# STM32F412Rx register map
File version: 1.0
Registers are 32-bit, read-write, reset 0x0 unless marked. A register's access mark holds for its fields unless they carry their own. Offsets are from the block's base; [hi:lo] are bit positions; {n}, {i} and the like mark numbered series; 'fields as' and 'values as' point back to an identical list.

## PWR — Power Control
Base 0x40007000
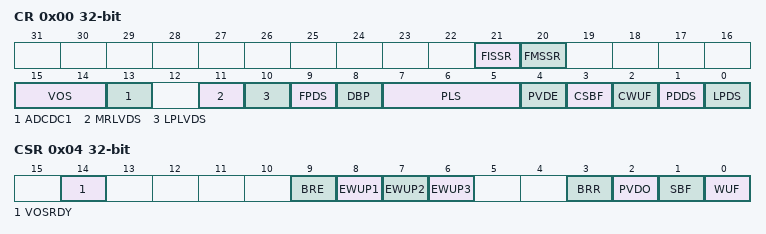
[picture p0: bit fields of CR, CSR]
0x00 CR — PWR power control register
  [21] FISSR — Flash Interface Stop while System Run
  [20] FMSSR — Flash Memory Sleep System Run
  [15:14] VOS — VOS[1:0] bits (Regulator voltage scaling output selection)
    3=SCALE1; 2=SCALE2; 1=SCALE3
  [13] ADCDC1 — Refer to AN4073 on how to use this bit
  [11] MRLVDS — Main Regulator Low Voltage in Deep Sleep mode
  [10] LPLVDS — Low Power Regulator Low Voltage in Deep Sleep mode
  [9] FPDS — Flash power down in Stop mode
  [8] DBP — Disable Backup Domain write protection
  [7:5] PLS — PLS[2:0] bits (PVD Level Selection)
    0=PVDLEVEL_0 (Voltage threshold detected by PVD 2.2 V); 1=PVDLEVEL_1 (Voltage threshold detected by PVD 2.3 V); 2=PVDLEVEL_2 (Voltage threshold detected by PVD 2.4 V); 3=PVDLEVEL_3 (Voltage threshold detected by PVD 2.5 V); 4=PVDLEVEL_4 (Voltage threshold detected by PVD 2.6 V); 5=PVDLEVEL_5 (Voltage threshold detected by PVD 2.7 V); 6=PVDLEVEL_6 (Voltage threshold detected by PVD 2.8 V); 7=PVDLEVEL_7 (Voltage threshold detected by PVD 2.9 V)
  [4] PVDE — Power Voltage Detector Enable
  [3] CSBF — Clear Standby Flag
  [2] CWUF — Clear Wakeup Flag
  [1] PDDS — Power Down Deepsleep
  [0] LPDS — Low-Power Deepsleep
    0=MAIN (Voltage Regulator in main mode during deepsleep mode); 1=LOW_POWER (Voltage Regulator in low-power mode during deepsleep mode)
0x04 CSR — PWR power control/status register
  [14] VOSRDY — Regulator voltage scaling output selection ready
  [9] BRE — Backup regulator enable
  [8] EWUP1 — Enable WKUP pin 1
  [7] EWUP2 — Enable WKUP pin 2
  [6] EWUP3 — Enable WKUP pin 3
  [3] BRR — Backup regulator ready
  [2] PVDO — PVD Output
  [1] SBF — Standby Flag
  [0] WUF — Wakeup Flag

## SYSCFG — System configuration controller
Base 0x40013800
0x00 MEMRMP — SYSCFG memory remap register
  [1:0] MEM_MODE — SYSCFG_Memory Remap Config
    0=FLASH (Main Flash memory mapped at 0x00000000); 1=SYSTEMFLASH (System Flash memory mapped at 0x00000000); 3=SRAM (SRAM1 mapped at 0x00000000); 2=FSMC (FSMC(NOR/PSRAM 1 and 2) mapped at 0x00000000)
0x04 PMC — SYSCFG peripheral mode configuration register
  [16] ADC1DC2 — Refer to AN4073 on how to use this bit
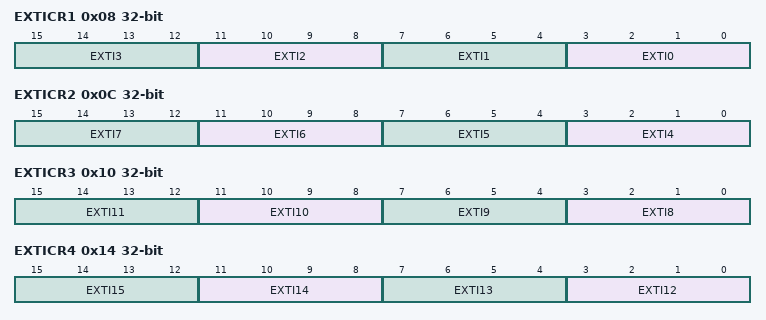
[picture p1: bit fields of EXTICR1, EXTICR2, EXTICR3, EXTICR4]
0x08 EXTICR1 — SYSCFG external interrupt configuration registers
  [4n+3:4n] EXTI{n} (n=0..3) — EXTI {n} configuration
0x0C EXTICR2 — SYSCFG external interrupt configuration registers
  [4n-13:4n-16] EXTI{n} (n=4..7) — EXTI {n} configuration
0x10 EXTICR3 — SYSCFG external interrupt configuration registers
  [4n-29:4n-32] EXTI{n} (n=8..11) — EXTI {n} configuration
0x14 EXTICR4 — SYSCFG external interrupt configuration registers
  [4n-45:4n-48] EXTI{n} (n=12..15) — EXTI {n} configuration
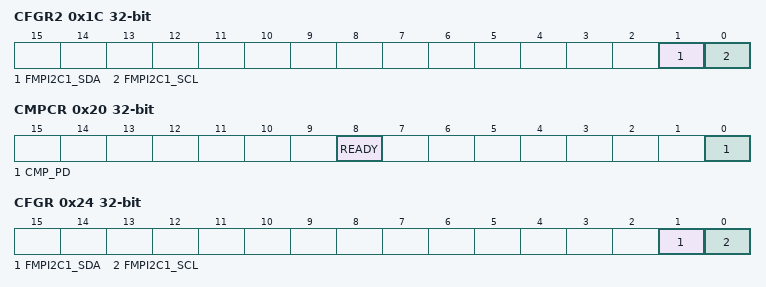
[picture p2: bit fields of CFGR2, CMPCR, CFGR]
0x1C CFGR2 — SYSCFG Configuration register2
  [1] FMPI2C1_SDA — FM+ drive capability for FMPI2C1_SDA pin
  [0] FMPI2C1_SCL — FM+ drive capability for FMPI2C1_SCL pin
0x20 CMPCR — SYSCFG Compensation cell control register
  [8] READY — Compensation cell power-down
  [0] CMP_PD — Compensation cell ready flag
0x24 CFGR — SYSCFG Configuration register
  fields as CFGR2

## EXTI — External Interrupt/Event Controller
Base 0x40013C00
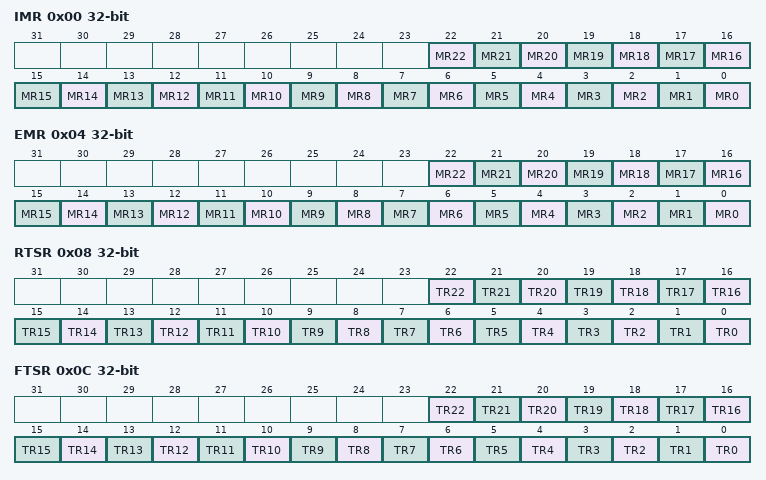
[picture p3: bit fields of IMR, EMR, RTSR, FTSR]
0x00 IMR — EXTI Interrupt mask register
  [n] MR{n} (n=0..22) — Interrupt Mask on line {n}
0x04 EMR — EXTI Event mask register
  [n] MR{n} (n=0..22) — Event Mask on line {n}
0x08 RTSR — EXTI Rising trigger selection register
  [n] TR{n} (n=0..22) — Rising trigger event configuration bit of line {n}
0x0C FTSR — EXTI Falling trigger selection register
  [n] TR{n} (n=0..22) — Falling trigger event configuration bit of line {n}
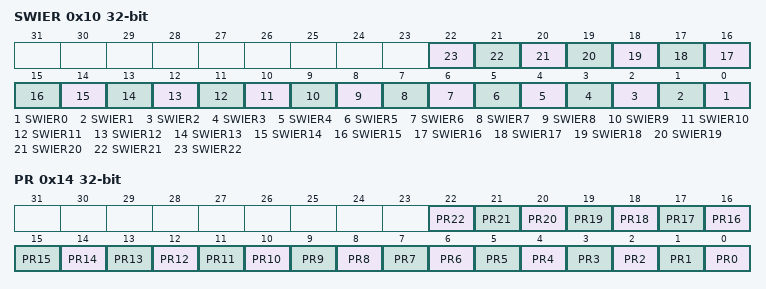
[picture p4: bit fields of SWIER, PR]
0x10 SWIER — EXTI Software interrupt event register
  [n] SWIER{n} (n=0..22) — Software Interrupt on line {n}
0x14 PR — EXTI Pending register
  [n] PR{n} (n=0..22) — Pending bit for line {n}
